AUTOSAR XML (schema 00052)
package /apd/AdaptiveApplicationSwComponentTypes
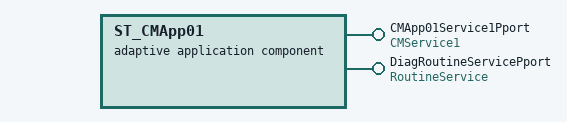
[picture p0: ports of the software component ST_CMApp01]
  adaptive application sw component type ST_CMApp01
    provide port CMApp01Service1Pport: provided-interface=CMService1
    provide port DiagRoutineServicePport: provided-interface=RoutineService
package /apd/Executables
  executable ST_CMApp01: category=APPLICATION_LEVEL, minimum-timer-granularity=1000.0
    root sw component prototype ST_CMApp01Root: application-type=ST_CMApp01
